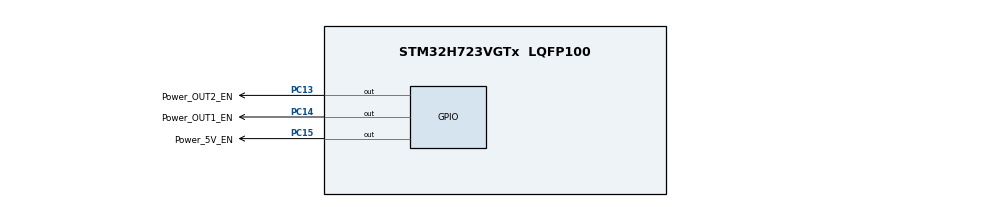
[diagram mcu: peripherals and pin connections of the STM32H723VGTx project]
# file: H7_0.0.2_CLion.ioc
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CORTEX_M7.CPU_ICache=Enabled
CORTEX_M7.MPU_Control=__NULL
CORTEX_M7.default_mode_Activation=1
FREERTOS.MEMORY_ALLOCATION=1
FREERTOS.Tasks01=defaultTask,0,128,StartDefaultTask,Default,NULL,Static,defaultTaskBuffer,defaultTaskControlBlock
FREERTOS.Timers01=myTimer01,Callback01,osTimerPeriodic,Default,NULL,Static,myTimer01ControlBlock;myTimer02,Callback02,osTimerPeriodic,Default,NULL,Static,myTimer02ControlBlock;myTimer03,Callback03,osTimerPeriodic,Default,NULL,Static,myTimer03ControlBlock
FREERTOS.configENABLE_FPU=1
FREERTOS.configUSE_NEWLIB_REENTRANT=1
FREERTOS.configUSE_TIMERS=1
FREERTOS.copyHeapFile=0
Mcu.Family=STM32H7
Mcu.Name=STM32H723VGTx
Mcu.Package=LQFP100
NVIC.PriorityGroup=NVIC_PRIORITYGROUP_4
NVIC.TIM6_DAC_IRQn=true\:15\:0\:false\:false\:true\:false\:false\:true\:true
NVIC.TimeBase=TIM6_DAC_IRQn
NVIC.TimeBaseIP=TIM6
PA13(JTMS/SWDIO).Mode=Serial_Wire
PA13(JTMS/SWDIO).Signal=DEBUG_JTMS-SWDIO
PA14(JTCK/SWCLK).Mode=Serial_Wire
PA14(JTCK/SWCLK).Signal=DEBUG_JTCK-SWCLK
PC13.GPIO_Label=Power_OUT2_EN
PC13.Signal=GPIO_Output
PC14-OSC32_IN.GPIO_Label=Power_OUT1_EN
PC14-OSC32_IN.Signal=GPIO_Output
PC15-OSC32_OUT.GPIO_Label=Power_5V_EN
PC15-OSC32_OUT.Signal=GPIO_Output
PH0-OSC_IN.Mode=HSE-External-Oscillator
PH0-OSC_IN.Signal=RCC_OSC_IN
PH1-OSC_OUT.Mode=HSE-External-Oscillator
PH1-OSC_OUT.Signal=RCC_OSC_OUT
ProjectManager.HeapSize=0x200
ProjectManager.StackSize=0x400
ProjectManager.TargetToolchain=STM32CubeIDE
RCC.ADCFreq_Value=48375000
RCC.APB1Freq_Value=137500000
RCC.APB2Freq_Value=137500000
RCC.APB3Freq_Value=137500000
RCC.APB4Freq_Value=137500000
RCC.CortexFreq_Value=550000000
RCC.D1PPRE=RCC_APB3_DIV2
RCC.D2PPRE1=RCC_APB1_DIV2
RCC.D2PPRE2=RCC_APB2_DIV2
RCC.D3PPRE=RCC_APB4_DIV2
RCC.DIVM1=3
RCC.DIVN1=68
RCC.DIVP1=1
RCC.HCLKFreq_Value=275000000
RCC.HPRE=RCC_HCLK_DIV2
RCC.HSE_VALUE=24000000
RCC.PLL2FRACN=0
RCC.PLL3FRACN=0
RCC.PLLFRACN=6144
RCC.PLLSourceVirtual=RCC_PLLSOURCE_HSE
RCC.SYSCLKFreq_VALUE=550000000
RCC.SYSCLKSource=RCC_SYSCLKSOURCE_PLLCLK
RCC.USBFreq_Value=275000000
VP_FREERTOS_VS_CMSIS_V1.Mode=CMSIS_V1
VP_MEMORYMAP_VS_MEMORYMAP.Mode=CurAppReg
VP_SYS_VS_tim6.Mode=TIM6
board=custom

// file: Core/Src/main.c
/* USER CODE BEGIN Header */
/**
  ******************************************************************************
  * @file           : main.c
  * @brief          : Main program body
  ******************************************************************************
  * @attention
  *
  * Copyright (c) 2026 STMicroelectronics.
  * All rights reserved.
  *
  * This software is licensed under terms that can be found in the LICENSE file
  * in the root directory of this software component.
  * If no LICENSE file comes with this software, it is provided AS-IS.
  *
  ******************************************************************************
  */
/* USER CODE END Header */
#include "main.h"
#include "cmsis_os.h"
#include "gpio.h"

void SystemClock_Config(void);
void MX_FREERTOS_Init(void);

int main(void)
{

  /* Enable the CPU Cache */

  /* Enable I-Cache---------------------------------------------------------*/
  SCB_EnableICache();

  /* MCU Configuration--------------------------------------------------------*/

  /* Reset of all peripherals, Initializes the Flash interface and the Systick. */
  HAL_Init();

  /* Configure the system clock */
  SystemClock_Config();

  /* Initialize all configured peripherals */
  MX_GPIO_Init();

  /* Call init function for freertos objects (in cmsis_os2.c) */
  MX_FREERTOS_Init();

  /* Start scheduler */
  osKernelStart();

  /* We should never get here as control is now taken by the scheduler */

  /* Infinite loop */
  /* USER CODE BEGIN WHILE */
  while (1)
  {
    // HAL_GPIO_TogglePin(Power_5V_EN_GPIO_Port,Power_5V_EN_Pin);
    // HAL_GPIO_TogglePin(Power_OUT2_EN_GPIO_Port,Power_OUT2_EN_Pin);
    // HAL_Delay((4000));
    // HAL_GPIO_TogglePin(Power_OUT1_EN_GPIO_Port,Power_OUT1_EN_Pin);

    /* USER CODE END WHILE */

  }
}

void SystemClock_Config(void)
{
  RCC_OscInitTypeDef RCC_OscInitStruct = {0};
  RCC_ClkInitTypeDef RCC_ClkInitStruct = {0};

  /** Supply configuration update enable
  */
  HAL_PWREx_ConfigSupply(PWR_LDO_SUPPLY);

  /** Configure the main internal regulator output voltage
  */
  __HAL_PWR_VOLTAGESCALING_CONFIG(PWR_REGULATOR_VOLTAGE_SCALE0);

  while(!__HAL_PWR_GET_FLAG(PWR_FLAG_VOSRDY)) {}

  /** Initializes the RCC Oscillators according to the specified parameters
  * in the RCC_OscInitTypeDef structure.
  */
  RCC_OscInitStruct.OscillatorType = RCC_OSCILLATORTYPE_HSE;
  RCC_OscInitStruct.HSEState = RCC_HSE_ON;
  RCC_OscInitStruct.PLL.PLLState = RCC_PLL_ON;
  RCC_OscInitStruct.PLL.PLLSource = RCC_PLLSOURCE_HSE;
  RCC_OscInitStruct.PLL.PLLM = 3;
  RCC_OscInitStruct.PLL.PLLN = 68;
  RCC_OscInitStruct.PLL.PLLP = 1;
  RCC_OscInitStruct.PLL.PLLQ = 2;
  RCC_OscInitStruct.PLL.PLLR = 2;
  RCC_OscInitStruct.PLL.PLLRGE = RCC_PLL1VCIRANGE_3;
  RCC_OscInitStruct.PLL.PLLVCOSEL = RCC_PLL1VCOWIDE;
  RCC_OscInitStruct.PLL.PLLFRACN = 6144;
  if (HAL_RCC_OscConfig(&RCC_OscInitStruct) != HAL_OK)
  {
    Error_Handler();
  }

  /** Initializes the CPU, AHB and APB buses clocks
  */
  RCC_ClkInitStruct.ClockType = RCC_CLOCKTYPE_HCLK|RCC_CLOCKTYPE_SYSCLK
                              |RCC_CLOCKTYPE_PCLK1|RCC_CLOCKTYPE_PCLK2
                              |RCC_CLOCKTYPE_D3PCLK1|RCC_CLOCKTYPE_D1PCLK1;
  RCC_ClkInitStruct.SYSCLKSource = RCC_SYSCLKSOURCE_PLLCLK;
  RCC_ClkInitStruct.SYSCLKDivider = RCC_SYSCLK_DIV1;
  RCC_ClkInitStruct.AHBCLKDivider = RCC_HCLK_DIV2;
  RCC_ClkInitStruct.APB3CLKDivider = RCC_APB3_DIV2;
  RCC_ClkInitStruct.APB1CLKDivider = RCC_APB1_DIV2;
  RCC_ClkInitStruct.APB2CLKDivider = RCC_APB2_DIV2;
  RCC_ClkInitStruct.APB4CLKDivider = RCC_APB4_DIV2;

  if (HAL_RCC_ClockConfig(&RCC_ClkInitStruct, FLASH_LATENCY_3) != HAL_OK)
  {
    Error_Handler();
  }
}

void HAL_TIM_PeriodElapsedCallback(TIM_HandleTypeDef *htim)
{
  if (htim->Instance == TIM6)
  {
    HAL_IncTick();
  }
}

void Error_Handler(void)
{
  __disable_irq();
  while (1)
  {
  }
}

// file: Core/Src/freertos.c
/* USER CODE BEGIN Header */
/**
  ******************************************************************************
  * File Name          : freertos.c
  * Description        : Code for freertos applications
  ******************************************************************************
  * @attention
  *
  * Copyright (c) 2026 STMicroelectronics.
  * All rights reserved.
  *
  * This software is licensed under terms that can be found in the LICENSE file
  * in the root directory of this software component.
  * If no LICENSE file comes with this software, it is provided AS-IS.
  *
  ******************************************************************************
  */
/* USER CODE END Header */

#include "FreeRTOS.h"
#include "task.h"
#include "main.h"
#include "cmsis_os.h"

osThreadId defaultTaskHandle;
uint32_t defaultTaskBuffer[ 128 ];
osStaticThreadDef_t defaultTaskControlBlock;
osTimerId myTimer01Handle;
osStaticTimerDef_t myTimer01ControlBlock;
osTimerId myTimer02Handle;
osStaticTimerDef_t myTimer02ControlBlock;
osTimerId myTimer03Handle;
osStaticTimerDef_t myTimer03ControlBlock;

void StartDefaultTask(void const * argument);
void Callback01(void const * argument);
void Callback02(void const * argument);
void Callback03(void const * argument);

void MX_FREERTOS_Init(void); /* (MISRA C 2004 rule 8.1) */

/* GetIdleTaskMemory prototype (linked to static allocation support) */
void vApplicationGetIdleTaskMemory( StaticTask_t **ppxIdleTaskTCBBuffer, StackType_t **ppxIdleTaskStackBuffer, uint32_t *pulIdleTaskStackSize );

/* GetTimerTaskMemory prototype (linked to static allocation support) */
void vApplicationGetTimerTaskMemory( StaticTask_t **ppxTimerTaskTCBBuffer, StackType_t **ppxTimerTaskStackBuffer, uint32_t *pulTimerTaskStackSize );

/* USER CODE BEGIN GET_IDLE_TASK_MEMORY */
static StaticTask_t xIdleTaskTCBBuffer;
static StackType_t xIdleStack[configMINIMAL_STACK_SIZE];

void vApplicationGetIdleTaskMemory( StaticTask_t **ppxIdleTaskTCBBuffer, StackType_t **ppxIdleTaskStackBuffer, uint32_t *pulIdleTaskStackSize )
{
  *ppxIdleTaskTCBBuffer = &xIdleTaskTCBBuffer;
  *ppxIdleTaskStackBuffer = &xIdleStack[0];
  *pulIdleTaskStackSize = configMINIMAL_STACK_SIZE;
  /* place for user code */
}
/* USER CODE END GET_IDLE_TASK_MEMORY */

/* USER CODE BEGIN GET_TIMER_TASK_MEMORY */
static StaticTask_t xTimerTaskTCBBuffer;
static StackType_t xTimerStack[configTIMER_TASK_STACK_DEPTH];

void vApplicationGetTimerTaskMemory( StaticTask_t **ppxTimerTaskTCBBuffer, StackType_t **ppxTimerTaskStackBuffer, uint32_t *pulTimerTaskStackSize )
{
  *ppxTimerTaskTCBBuffer = &xTimerTaskTCBBuffer;
  *ppxTimerTaskStackBuffer = &xTimerStack[0];
  *pulTimerTaskStackSize = configTIMER_TASK_STACK_DEPTH;
  /* place for user code */
}
/* USER CODE END GET_TIMER_TASK_MEMORY */

void MX_FREERTOS_Init(void) {

  /* Create the timer(s) */
  /* definition and creation of myTimer01 */
  osTimerStaticDef(myTimer01, Callback01, &myTimer01ControlBlock);
  myTimer01Handle = osTimerCreate(osTimer(myTimer01), osTimerPeriodic, NULL);

  /* definition and creation of myTimer02 */
  osTimerStaticDef(myTimer02, Callback02, &myTimer02ControlBlock);
  myTimer02Handle = osTimerCreate(osTimer(myTimer02), osTimerPeriodic, NULL);

  /* definition and creation of myTimer03 */
  osTimerStaticDef(myTimer03, Callback03, &myTimer03ControlBlock);
  myTimer03Handle = osTimerCreate(osTimer(myTimer03), osTimerPeriodic, NULL);

  /* USER CODE BEGIN RTOS_TIMERS */
  /* start timers, add new ones, ... */
  osTimerStart(myTimer01Handle,2000);
  osTimerStart(myTimer02Handle,5000);
  /* USER CODE END RTOS_TIMERS */

  /* Create the thread(s) */
  /* definition and creation of defaultTask */
  osThreadStaticDef(defaultTask, StartDefaultTask, osPriorityNormal, 0, 128, defaultTaskBuffer, &defaultTaskControlBlock);
  defaultTaskHandle = osThreadCreate(osThread(defaultTask), NULL);

}

void StartDefaultTask(void const * argument)
{
  /* USER CODE BEGIN StartDefaultTask */
  // HAL_GPIO_TogglePin(Power_OUT1_EN_GPIO_Port,Power_OUT1_EN_Pin);
  /* Infinite loop */
  for(;;)
  {
    osDelay(1);
  }
  /* USER CODE END StartDefaultTask */
}

/* Callback01 function */
void Callback01(void const * argument)
{
  /* USER CODE BEGIN Callback01 */
  HAL_GPIO_TogglePin(Power_OUT1_EN_GPIO_Port,Power_OUT1_EN_Pin);
  HAL_GPIO_TogglePin(Power_OUT2_EN_GPIO_Port,Power_OUT2_EN_Pin);
  /* USER CODE END Callback01 */
}

/* Callback02 function */
void Callback02(void const * argument)
{
  /* USER CODE BEGIN Callback02 */
  HAL_GPIO_TogglePin(Power_5V_EN_GPIO_Port,Power_5V_EN_Pin);
  /* USER CODE END Callback02 */
}

/* Callback03 function */
void Callback03(void const * argument)
{
}
